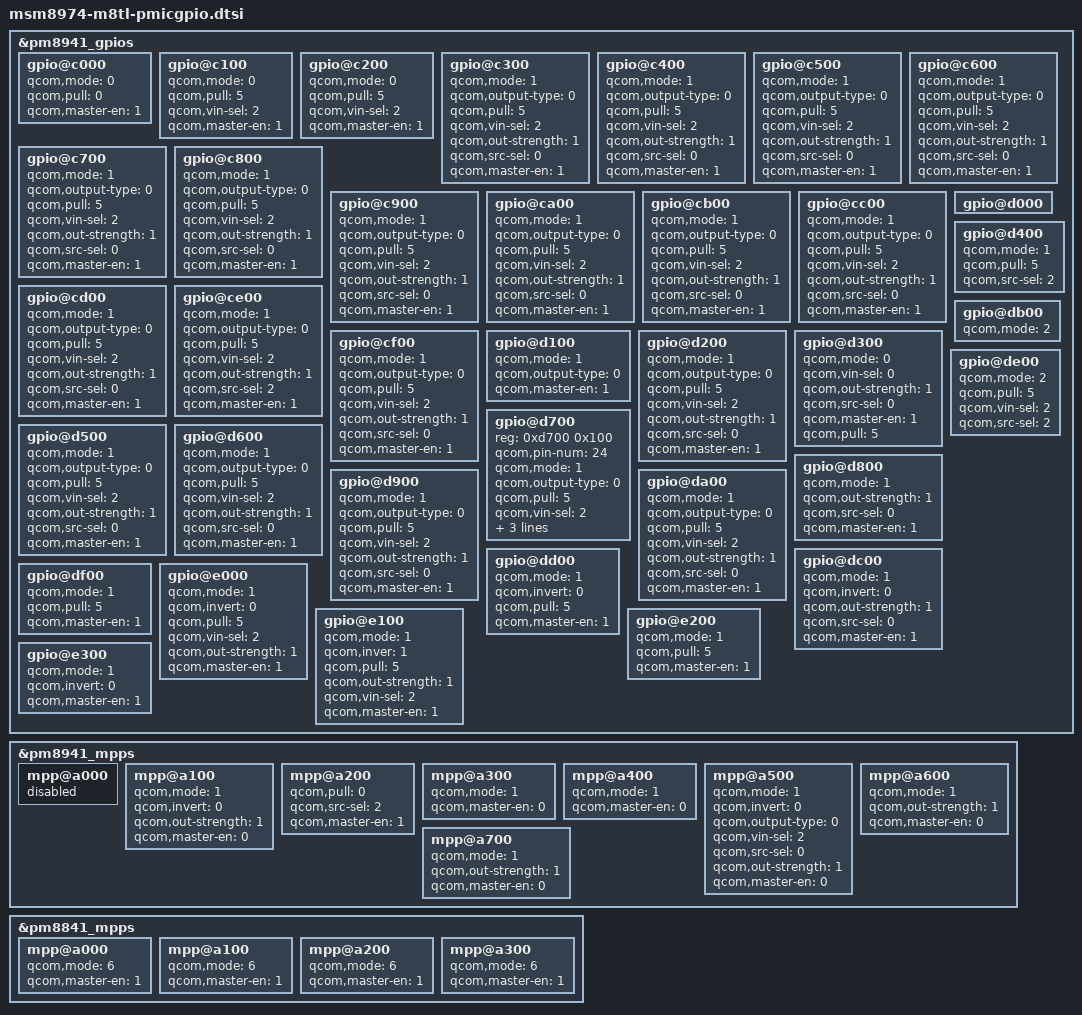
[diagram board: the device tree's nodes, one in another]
/* Copyright (c) 2012-2013, The Linux Foundation. All rights reserved.
 *
 * This program is free software; you can redistribute it and/or modify
 * it under the terms of the GNU General Public License version 2 and
 * only version 2 as published by the Free Software Foundation.
 *
 * This program is distributed in the hope that it will be useful,
 * but WITHOUT ANY WARRANTY; without even the implied warranty of
 * MERCHANTABILITY or FITNESS FOR A PARTICULAR PURPOSE.  See the
 * GNU General Public License for more details.
 */

&pm8941_gpios {
	gpio@c000 { /* GPIO 1 */
		qcom,mode = <0>;		/* QPNP_PIN_MODE_DIG_IN */
		qcom,pull = <0>;		/* QPNP_PIN_PULL_UP_30  */
		qcom,master-en = <1>;
	};

	gpio@c100 { /* GPIO 2 */
		qcom,mode = <0>;		/* QPNP_PIN_MODE_DIG_IN */
		qcom,pull = <5>;		/* QPNP_PIN_PULL_NO */
		qcom,vin-sel = <2>;
		qcom,master-en = <1>;
	};

	gpio@c200 { /* GPIO 3 */
		qcom,mode = <0>;		/* QPNP_PIN_MODE_DIG_IN */
		qcom,pull = <5>;		/* QPNP_PIN_PULL_NO */
		qcom,vin-sel = <2>;
		qcom,master-en = <1>;
	};

	gpio@c300 { /* GPIO 4 */
		qcom,mode = <1>;		/* QPNP_PIN_MODE_DIG_OUT */
		qcom,output-type = <0>;		/* QPNP_PIN_OUT_BUF_CMOS */
		qcom,pull = <5>;		/* QPNP_PIN_PULL_NO */
		qcom,vin-sel = <2>;		/* QPNP_PIN_VIN2  */
		qcom,out-strength = <1>;	/* QPNP_PIN_OUT_STRENGTH_LOW */
		qcom,src-sel = <0>;		/* QPNP_PIN_SEL_FUNC_CONSTANT */
		qcom,master-en = <1>;
	};

	gpio@c400 { /* GPIO 5 */
		qcom,mode = <1>;		/* QPNP_PIN_MODE_DIG_OUT */
		qcom,output-type = <0>;		/* QPNP_PIN_OUT_BUF_CMOS */
		qcom,pull = <5>;		/* QPNP_PIN_PULL_NO */
		qcom,vin-sel = <2>;		/* QPNP_PIN_VIN2  */
		qcom,out-strength = <1>;	/* QPNP_PIN_OUT_STRENGTH_LOW */
		qcom,src-sel = <0>;		/* QPNP_PIN_SEL_FUNC_CONSTANT */
		qcom,master-en = <1>;
	};

	gpio@c500 { /* GPIO 6 */
		qcom,mode = <1>;		/* QPNP_PIN_MODE_DIG_OUT */
		qcom,output-type = <0>;		/* QPNP_PIN_OUT_BUF_CMOS */
		qcom,pull = <5>;		/* QPNP_PIN_PULL_NO */
		qcom,vin-sel = <2>;		/* QPNP_PIN_VIN2  */
		qcom,out-strength = <1>;	/* QPNP_PIN_OUT_STRENGTH_LOW */
		qcom,src-sel = <0>;		/* QPNP_PIN_SEL_FUNC_CONSTANT */
		qcom,master-en = <1>;
	};

	gpio@c600 { /* GPIO 7 , HS_2v85*/
		qcom,mode = <1>;		/* QPNP_PIN_MODE_DIG_OUT */
		qcom,output-type = <0>;		/* QPNP_PIN_OUT_BUF_CMOS */
		qcom,pull = <5>;		/* QPNP_PIN_PULL_NO */
		qcom,vin-sel = <2>;		/* QPNP_PIN_VIN2  */
		qcom,out-strength = <1>;	/* QPNP_PIN_OUT_STRENGTH_LOW */
		qcom,src-sel = <0>;		/* QPNP_PIN_SEL_FUNC_CONSTANT */
		qcom,master-en = <1>;
	};

	gpio@c700 { /* GPIO 8 -[CAM] RAW_1V2_EN- */
		qcom,mode = <1>;
		qcom,output-type = <0>;
		qcom,pull = <5>;
		qcom,vin-sel = <2>;
		qcom,out-strength = <1>;
		qcom,src-sel = <0>;
		qcom,master-en = <1>;
	};

	gpio@c800 { /* GPIO 9 -[CAM] CAM2_ID- */
		qcom,mode = <1>;		/* QPNP_PIN_MODE_DIG_OUT */
		qcom,output-type = <0>;		/* QPNP_PIN_OUT_BUF_CMOS */
		qcom,pull = <5>;		/* QPNP_PIN_PULL_NO */
		qcom,vin-sel = <2>;		/* QPNP_PIN_VIN2 */
		qcom,out-strength = <1>;	/* QPNP_PIN_OUT_STRENGTH_LOW */
		qcom,src-sel = <0>;		/* QPNP_PIN_SEL_FUNC_CONSTANT */
		qcom,master-en = <1>;
	};

	gpio@c900 { /* GPIO 10 -[CAM] MAIN_CAM_ID- */
		qcom,mode = <1>;		/* QPNP_PIN_MODE_DIG_OUT */
		qcom,output-type = <0>;		/* QPNP_PIN_OUT_BUF_CMOS */
		qcom,pull = <5>;		/* QPNP_PIN_PULL_NO */
		qcom,vin-sel = <2>;		/* QPNP_PIN_VIN2 */
		qcom,out-strength = <1>;	/* QPNP_PIN_OUT_STRENGTH_LOW */
		qcom,src-sel = <0>;		/* QPNP_PIN_SEL_FUNC_CONSTANT */
		qcom,master-en = <1>;
	};

	gpio@ca00 { /* GPIO 11 -[CAM] CAM_VCM_PD- */
		qcom,mode = <1>;		/* QPNP_PIN_MODE_DIG_OUT */
		qcom,output-type = <0>;		/* QPNP_PIN_OUT_BUF_CMOS */
		qcom,pull = <5>;		/* QPNP_PIN_PULL_NO */
		qcom,vin-sel = <2>;		/* QPNP_PIN_VIN2 */
		qcom,out-strength = <1>;	/* QPNP_PIN_OUT_STRENGTH_LOW */
		qcom,src-sel = <0>;		/* QPNP_PIN_SEL_FUNC_CONSTANT */
		qcom,master-en = <1>;
	};

	gpio@cb00 { /* GPIO 12 -[CAM] CAM_PWDN- */
		qcom,mode = <1>;
		qcom,output-type = <0>;
		qcom,pull = <5>;
		qcom,vin-sel = <2>;
		qcom,out-strength = <1>;
		qcom,src-sel = <0>;
		qcom,master-en = <1>;
	};

	gpio@cc00 { /* GPIO 13 -[CAM] CAM2_RST#- */
		qcom,mode = <1>;		/* QPNP_PIN_MODE_DIG_OUT */
		qcom,output-type = <0>;
		qcom,pull = <5>;
		qcom,vin-sel = <2>;
		qcom,out-strength = <1>;	/* QPNP_PIN_OUT_STRENGTH_LOW */
		qcom,src-sel = <0>;		/* QPNP_PIN_SEL_FUNC_1  */
		qcom,master-en = <1>;
	};

	gpio@cd00 { /* GPIO 14 -[CAM]RAW_RST#- */
		qcom,mode = <1>;		/* QPNP_PIN_MODE_DIG_OUT */
		qcom,output-type = <0>;
		qcom,pull = <5>;
		qcom,vin-sel = <2>;
		qcom,out-strength = <1>;	/* QPNP_PIN_OUT_STRENGTH_LOW */
		qcom,src-sel = <0>;
		qcom,master-en = <1>;
	};

	gpio@ce00 { /* GPIO 15 */
		qcom,mode = <1>;
		qcom,output-type = <0>;
		qcom,pull = <5>;
		qcom,vin-sel = <2>;
		qcom,out-strength = <1>;
		qcom,src-sel = <2>;
		qcom,master-en = <1>;
	};

	gpio@cf00 { /* GPIO 16 */
		qcom,mode = <1>;
		qcom,output-type = <0>;
		qcom,pull = <5>;
		qcom,vin-sel = <2>;
		qcom,out-strength = <1>;
		qcom,src-sel = <0>;		/* QPNP_PIN_SEL_FUNC_2  */
		qcom,master-en = <1>;
	};

	gpio@d000 { /* GPIO 17 */
	};

	gpio@d100 { /* GPIO 18 */
		qcom,mode = <1>;
		qcom,output-type = <0>;
		qcom,master-en = <1>;
	};

	gpio@d200 { /* GPIO 19 */
		qcom,mode = <1>;		/* QPNP_PIN_MODE_DIG_OUT */
		qcom,output-type = <0>;		/* QPNP_PIN_OUT_BUF_CMOS */
		qcom,pull = <5>;		/* QPNP_PIN_PULL_NO */
		qcom,vin-sel = <2>;		/* QPNP_PIN_VIN2 */
		qcom,out-strength = <1>;	/* QPNP_PIN_OUT_STRENGTH_LOW */
		qcom,src-sel = <0>;		/* QPNP_PIN_SEL_FUNC_CONSTANT */
		qcom,master-en = <1>;
	};

	gpio@d300 { /* GPIO 20 */
		qcom,mode = <0>;		/* QPNP_PIN_MODE_DIG_OUT */
		qcom,vin-sel = <0>;
		qcom,out-strength = <1>;	/* QPNP_PIN_OUT_STRENGTH_LOW */
		qcom,src-sel = <0>;		/* QPNP_PIN_SEL_FUNC_CONSTANT */
		qcom,master-en = <1>;
		qcom,pull = <5>;
	};

	gpio@d400 { /* GPIO 21 */
		qcom,mode = <1>;
		qcom,pull = <5>;
		qcom,src-sel = <2>;
	};

	gpio@d500 { /* GPIO 22 -[CAM] CAM_VCM2V85_EN- */
		qcom,mode = <1>;
		qcom,output-type = <0>;
		qcom,pull = <5>;
		qcom,vin-sel = <2>;
		qcom,out-strength = <1>;
		qcom,src-sel = <0>;
		qcom,master-en = <1>;
	};

	gpio@d600 { /* GPIO 23 -[CAM] CAM_D1V2_EN */
		qcom,mode = <1>;
		qcom,output-type = <0>;
		qcom,pull = <5>;
		qcom,vin-sel = <2>;
		qcom,out-strength = <1>;
		qcom,src-sel = <0>;
		qcom,master-en = <1>;
	};

	gpio@d700 { /* GPIO 24 */
		reg = <0xd700 0x100>;
		qcom,pin-num = <24>;
		qcom,mode = <1>;		/* QPNP_PIN_MODE_DIG_OUT */
		qcom,output-type = <0>;		/* QPNP_PIN_OUT_BUF_CMOS */
		qcom,pull = <5>;		/* QPNP_PIN_PULL_NO */
		qcom,vin-sel = <2>;		/* QPNP_PIN_VIN2 */
		qcom,out-strength = <1>;	/* QPNP_PIN_OUT_STRENGTH_HIGH */
		qcom,src-sel = <0>;		/* QPNP_PIN_SEL_FUNC_2 : LPG*/
		qcom,master-en = <1>;
	};

	gpio@d800 { /* GPIO 25 */
		qcom,mode = <1>;		/* QPNP_PIN_MODE_DIG_OUT */
		qcom,out-strength = <1>;	/* QPNP_PIN_OUT_STRENGTH_LOW */
		qcom,src-sel = <0>;		/* QPNP_PIN_SEL_FUNC_1  */
		qcom,master-en = <1>;
	};

	gpio@d900 { /* GPIO 26 */
		qcom,mode = <1>;		/* QPNP_PIN_MODE_DIG_OUT */
		qcom,output-type = <0>;		/* QPNP_PIN_OUT_BUF_CMOS */
		qcom,pull = <5>;		/* QPNP_PIN_PULL_NO */
		qcom,vin-sel = <2>;		/* QPNP_PIN_VIN2 */
		qcom,out-strength = <1>;	/* QPNP_PIN_OUT_STRENGTH_LOW */
		qcom,src-sel = <0>;		/* QPNP_PIN_SEL_FUNC_CONSTANT */
		qcom,master-en = <1>;
	};

	gpio@da00 { /* GPIO 27 */
		qcom,mode = <1>;		/* QPNP_PIN_MODE_DIG_OUT */
		qcom,output-type = <0>;		/* QPNP_PIN_OUT_BUF_CMOS */
		qcom,pull = <5>;		/* QPNP_PIN_PULL_NO */
		qcom,vin-sel = <2>;		/* QPNP_PIN_VIN2 */
		qcom,out-strength = <1>;	/* QPNP_PIN_OUT_STRENGTH_LOW */
		qcom,src-sel = <0>;		/* QPNP_PIN_SEL_FUNC_CONSTANT */
		qcom,master-en = <1>;
	};

	gpio@db00 { /* GPIO 28 */
		qcom,mode = <2>;
	};

	gpio@dc00 { /* GPIO 29 */
		qcom,mode = <1>;		/* QPNP_PIN_MODE_DIG_OUT */
		qcom,invert = <0>;
		qcom,out-strength = <1>;	/* QPNP_PIN_OUT_STRENGTH_LOW */
		qcom,src-sel = <0>;		/* QPNP_PIN_SEL_FUNC_1  */
		qcom,master-en = <1>;
	};

	gpio@dd00 { /* GPIO 30 */
		qcom,mode = <1>;		/* QPNP_PIN_MODE_DIG_OUT */
		qcom,invert = <0>;
		qcom,pull = <5>;		/* QPNP_PIN_PULL_NO */
		qcom,master-en = <1>;
	};

	gpio@de00 { /* GPIO 31 */
		qcom,mode = <2>;
		qcom,pull = <5>;
		qcom,vin-sel = <2>;
		qcom,src-sel = <2>;
	};

	gpio@df00 { /* GPIO 32 */
		qcom,mode = <1>;        	/* QPNP_PIN_MODE_DIG_IN */
		qcom,pull = <5>;		/* QPNP_PIN_PULL_NO */
		qcom,master-en = <1>;
	};

	gpio@e000 { /* GPIO 33 */
		qcom,mode = <1>;		/* QPNP_PIN_MODE_DIG_OUT */
		qcom,invert = <0>;
		qcom,pull = <5>;		/* QPNP_PIN_PULL_NO */
		qcom,vin-sel = <2>;
		qcom,out-strength = <1>;
		qcom,master-en = <1>;
	};

	gpio@e100 { /* GPIO 34 */
		qcom,mode = <1>;		/* QPNP_PIN_MODE_DIG_OUT */
		qcom,inver = <1>;
		qcom,pull = <5>;		/* QPNP_PIN_PULL_NO */
		qcom,out-strength = <1>;
		qcom,vin-sel = <2>;
		qcom,master-en = <1>;
	};

	gpio@e200 { /* GPIO 35 */
		qcom,mode = <1>;		/* QPNP_PIN_MODE_DIG_IN */
		qcom,pull = <5>;		/* QPNP_PIN_PULL_NO */
		qcom,master-en = <1>;
	};

	gpio@e300 { /* GPIO 36 */
		qcom,mode = <1>;
		qcom,invert = <0>;
		qcom,master-en = <1>;
	};
};

&pm8941_mpps {

	mpp@a000 { /* MPP 1 */
		status = "disabled";
	};

	mpp@a100 { /* MPP 2 */
		qcom,mode = <1>;		/* QPNP_PIN_MODE_DIG_OUT */
		qcom,invert = <0>;
		qcom,out-strength = <1>;	/* QPNP_PIN_OUT_STRENGTH_LOW */
		qcom,master-en = <0>;
	};

	mpp@a200 { /* MPP 3 */
		qcom,pull = <0>;
		qcom,src-sel = <2>;
		qcom,master-en = <1>;
	};

	mpp@a300 { /* MPP 4 */
		qcom,mode = <1>;
		qcom,master-en = <0>;
	};

	mpp@a400 { /* MPP 5 */
		qcom,mode = <1>;
		qcom,master-en = <0>;
	};

	mpp@a500 { /* MPP 6 */
		qcom,mode = <1>;		/* DIG_IN */
		qcom,invert = <0>;
		qcom,output-type = <0>;		/* CMOS */
		qcom,vin-sel = <2>;		/* PM8941_S3 1.8V > 1.6V */
		qcom,src-sel = <0>;		/* CONSTANT */
		qcom,out-strength = <1>;	/* QPNP_PIN_OUT_STRENGTH_LOW */
		qcom,master-en = <0>;		/* ENABLE MPP */
	};

	mpp@a600 { /* MPP 7 */
		qcom,mode = <1>;		/* QPNP_PIN_MODE_DIG_OUT */
		qcom,out-strength = <1>;	/* QPNP_PIN_OUT_STRENGTH_LOW */
		qcom,master-en = <0>;
	};

	mpp@a700 { /* MPP 8 */
		qcom,mode = <1>;		/* QPNP_PIN_MODE_DIG_OUT */
		qcom,out-strength = <1>;	/* QPNP_PIN_OUT_STRENGTH_LOW */
		qcom,master-en = <0>;
	};
};

&pm8841_mpps {

	mpp@a000 { /* MPP 1 */
		qcom,mode = <6>;
		qcom,master-en = <1>;
	};

	mpp@a100 { /* MPP 2 */
		qcom,mode = <6>;
		qcom,master-en = <1>;
	};

	mpp@a200 { /* MPP 3 */
		qcom,mode = <6>;
		qcom,master-en = <1>;
	};

	mpp@a300 { /* MPP 4 */
		qcom,mode = <6>;
		qcom,master-en = <1>;
	};
};

